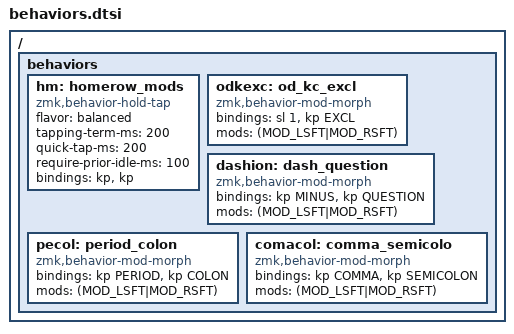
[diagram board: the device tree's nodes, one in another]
#include <behaviors.dtsi>

/ {
    behaviors {
        hm: homerow_mods {
            compatible = "zmk,behavior-hold-tap";
            #binding-cells = <2>;
            flavor = "balanced";
            tapping-term-ms = <200>;
            quick-tap-ms = <200>; // Double tapping -> hold key
            require-prior-idle-ms = <100>;  
            bindings = <&kp>, <&kp>;
        };

        // Ergo-l keys
        odkexc: od_kc_excl {
            compatible = "zmk,behavior-mod-morph";
            #binding-cells = <0>;
            bindings = <&sl 1>, <&kp EXCL>;
            mods = <(MOD_LSFT|MOD_RSFT)>;
        };

        dashion: dash_question {
            compatible = "zmk,behavior-mod-morph";
            #binding-cells = <0>;
            bindings = <&kp MINUS>, <&kp QUESTION>;
            mods = <(MOD_LSFT|MOD_RSFT)>;
        };

        pecol: period_colon {
            compatible = "zmk,behavior-mod-morph";
            #binding-cells = <0>;
            bindings = <&kp PERIOD>, <&kp COLON>;
            mods = <(MOD_LSFT|MOD_RSFT)>;
        };

        comacol: comma_semicolo {
            compatible = "zmk,behavior-mod-morph";
            #binding-cells = <0>;
            bindings = <&kp COMMA>, <&kp SEMICOLON>;
            mods = <(MOD_LSFT|MOD_RSFT)>;
        };

        // TODO Unused atm, not playing well w/ interruptions (tap-e -> qeu)
        // qu_q: tap_dance_0 {
        //     compatible = "zmk,behavior-tap-dance";
        //     label = "TAP_DANCE_0";
        //     #binding-cells = <0>;
        //     bindings = <&qu>, <&kp Q>;
        // };

    };
};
